# VPAC0_COMMON_0_PAR_VPAC_VISS0_S_VBUSP_VISS_FCP2_FCC_VBUSP_FLEXCC_LINE register map
Vendor: Texas Instruments
Peripheral module from a debugger description file (folder J7_AHP).
Registers are 32-bit, read-write, reset 0x0 unless marked. A register's access mark holds for its fields unless they carry their own. Offsets are as the file gives them; lines under a group give offsets from that group; [hi:lo] are bit positions; {n}, {i} and the like mark numbered series; 'fields as' and 'values as' point back to an identical list; <NAME> marks a mode.

## VPAC0_COMMON_0_PAR_VPAC_VISS0_S_VBUSP_VISS_FCP2_FCC_VBUSP_FLEXCC_LINE
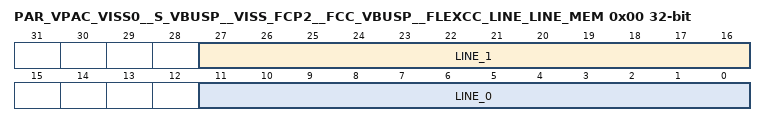
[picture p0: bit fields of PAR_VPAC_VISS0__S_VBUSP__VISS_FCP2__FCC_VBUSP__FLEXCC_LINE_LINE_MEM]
0x00 PAR_VPAC_VISS0__S_VBUSP__VISS_FCP2__FCC_VBUSP__FLEXCC_LINE_LINE_MEM
  [27:16] LINE_1, [11:0] LINE_0
